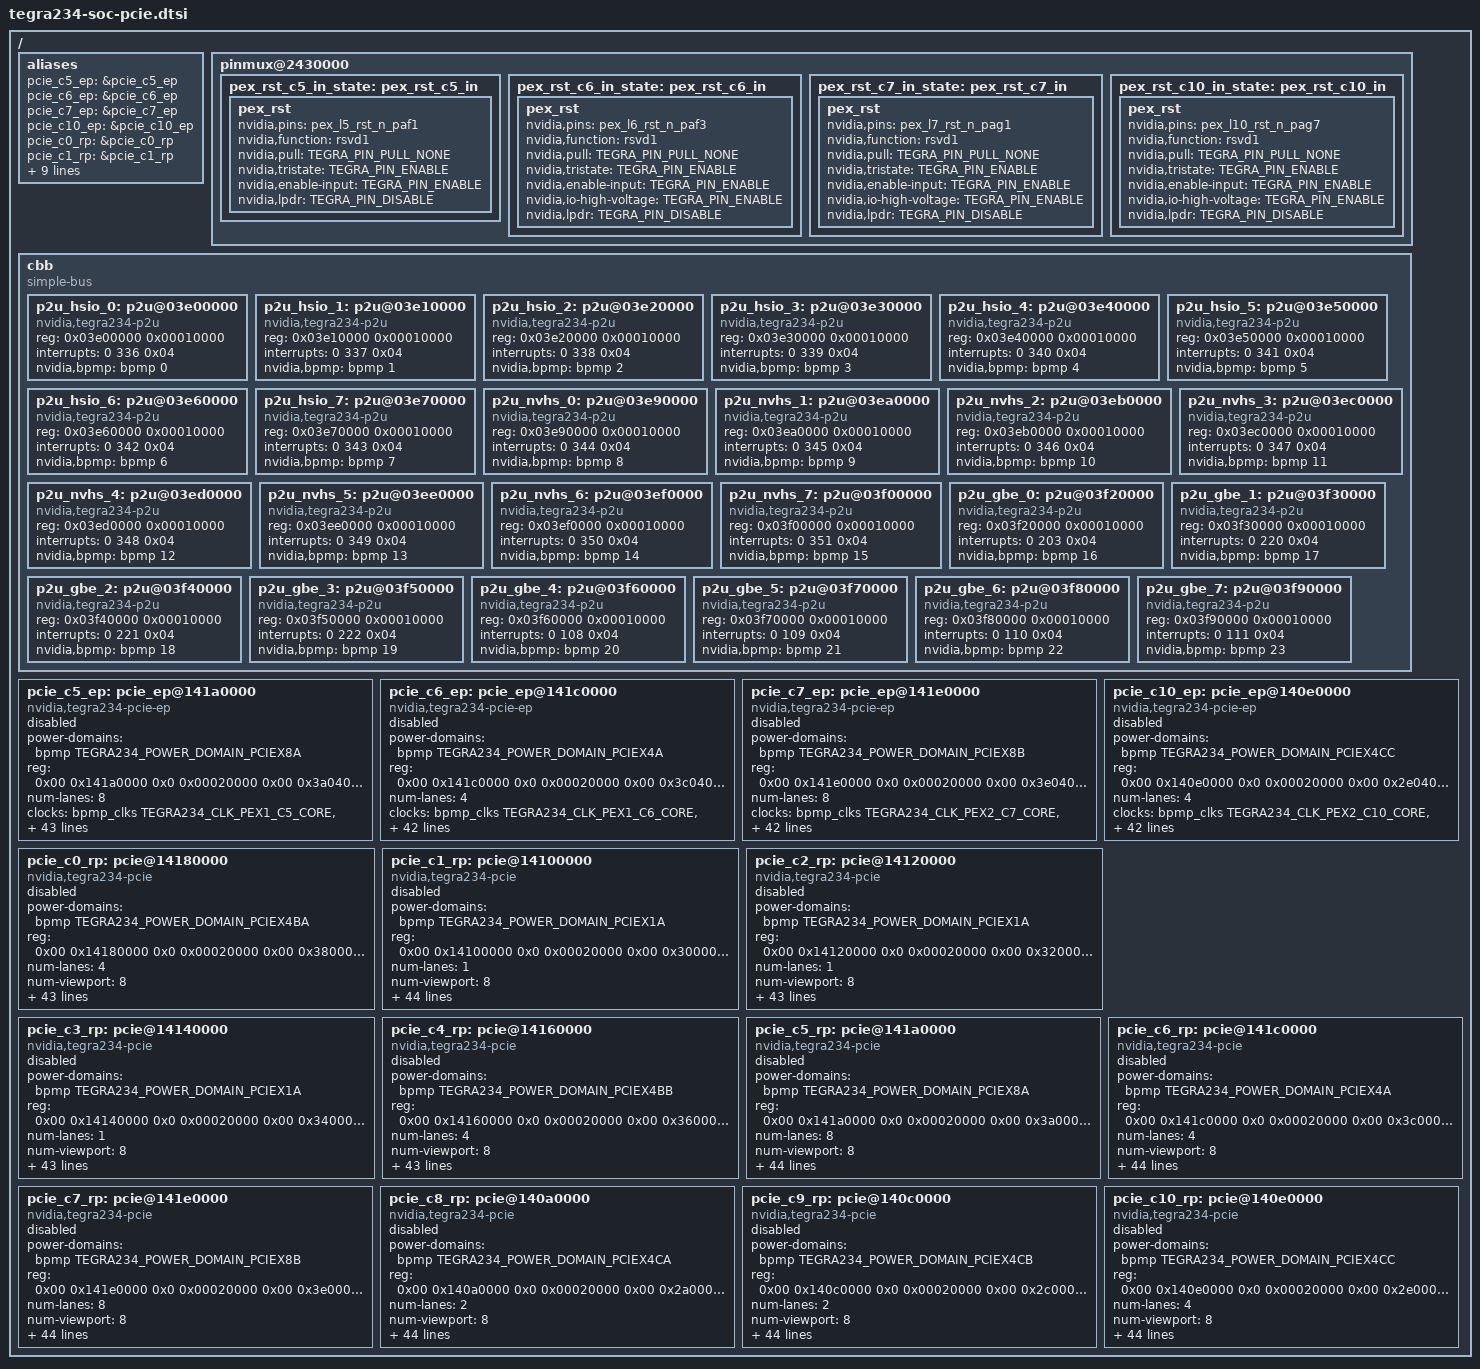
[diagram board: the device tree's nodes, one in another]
/*
 * Copyright (c) 2017-2021, NVIDIA CORPORATION.  All rights reserved.
 *
 * This program is free software; you can redistribute it and/or modify it
 * under the terms and conditions of the GNU General Public License,
 * version 2, as published by the Free Software Foundation.
 *
 * This program is distributed in the hope it will be useful, but WITHOUT
 * ANY WARRANTY; without even the implied warranty of MERCHANTABILITY or
 * FITNESS FOR A PARTICULAR PURPOSE.  See the GNU General Public License for
 * more details.
 *
 * You should have received a copy of the GNU General Public License
 * along with this program.  If not, see <http://www.gnu.org/licenses/>.
 */

#include <dt-bindings/clock/tegra234-clock.h>
#include <dt-bindings/memory/tegra234-mc.h>
#include <dt-bindings/reset/tegra234-reset.h>
#include <dt-bindings/interconnect/tegra_icc_id.h>

/*
 * Power domain to PCIE controller and chiplet mapping
 * +---------+-----------------+---------------+--------------+
 * | Sr. No. | PCIE Controller |    Chiplet    | Power domain |
 * +---------+-----------------+---------------+--------------+
 * |       1 | PCIE_C0         | hsiouphy_pcie | pciex4b (b0) |
 * |       2 | PCIE_C1 *       | hsiouphy_pcie | pciex1a      |
 * |       3 | PCIE_C2 *       | hsiouphy_pcie | pciex1a      |
 * |       4 | PCIE_C3 *       | hsiouphy_pcie | pciex1a      |
 * |       5 | PCIE_C4         | hsiouphy_pcie | pciex4c (b1) |
 * |       6 | PCIE_C5 *       | nvlinkuphy    | pciex8a      |
 * |       7 | PCIE_C6         | nvlinkuphy    | pciex4a      |
 * |       8 | PCIE_C7 *       | mgbeuphy_pcie | pciex8b      |
 * |       9 | PCIE_C8         | mgbeuphy_pcie | pciex4d      |
 * |      10 | PCIE_C9         | mgbeuphy_pcie | pciex4e      |
 * |      11 | PCIE_C10        | mgbeuphy_pcie | pciex4f      |
 * +---------+-----------------+---------------+--------------+
 *
 * *) Power domain in chiplet that needs to be on when other power domains in
 *    the chiplet are on.
 *    I.e. the following "parent-child" relations exists:
 *    pciex1a: pciex4b0, pciex4b1
 *    pciex8a: pciex4a
 *    pciex8b: pciex4d, pciex4e, pciex4f
 *    This "parent-child" relation is taken care in BPMP FW.
 */

/ {

	aliases {
		pcie_c5_ep = &pcie_c5_ep;
		pcie_c6_ep = &pcie_c6_ep;
		pcie_c7_ep = &pcie_c7_ep;
		pcie_c10_ep = &pcie_c10_ep;
		pcie_c0_rp = &pcie_c0_rp;
		pcie_c1_rp = &pcie_c1_rp;
		pcie_c2_rp = &pcie_c2_rp;
		pcie_c3_rp = &pcie_c3_rp;
		pcie_c4_rp = &pcie_c4_rp;
		pcie_c5_rp = &pcie_c5_rp;
		pcie_c6_rp = &pcie_c6_rp;
		pcie_c7_rp = &pcie_c7_rp;
		pcie_c8_rp = &pcie_c8_rp;
		pcie_c9_rp = &pcie_c9_rp;
		pcie_c10_rp = &pcie_c10_rp;
	};

	pinmux@2430000 {

		pex_rst_c5_in_state: pex_rst_c5_in {
			pex_rst {
				nvidia,pins = "pex_l5_rst_n_paf1";
				nvidia,function = "rsvd1";
				nvidia,pull = <TEGRA_PIN_PULL_NONE>;
				nvidia,tristate = <TEGRA_PIN_ENABLE>;
				nvidia,enable-input = <TEGRA_PIN_ENABLE>;
				nvidia,lpdr = <TEGRA_PIN_DISABLE>;
			};
		};

		pex_rst_c6_in_state: pex_rst_c6_in {
			pex_rst {
				nvidia,pins = "pex_l6_rst_n_paf3";
				nvidia,function = "rsvd1";
				nvidia,pull = <TEGRA_PIN_PULL_NONE>;
				nvidia,tristate = <TEGRA_PIN_ENABLE>;
				nvidia,enable-input = <TEGRA_PIN_ENABLE>;
				nvidia,io-high-voltage = <TEGRA_PIN_ENABLE>;
				nvidia,lpdr = <TEGRA_PIN_DISABLE>;
			};
		};

		pex_rst_c7_in_state: pex_rst_c7_in {
			pex_rst {
				nvidia,pins = "pex_l7_rst_n_pag1";
				nvidia,function = "rsvd1";
				nvidia,pull = <TEGRA_PIN_PULL_NONE>;
				nvidia,tristate = <TEGRA_PIN_ENABLE>;
				nvidia,enable-input = <TEGRA_PIN_ENABLE>;
				nvidia,io-high-voltage = <TEGRA_PIN_ENABLE>;
				nvidia,lpdr = <TEGRA_PIN_DISABLE>;
			};
		};

		pex_rst_c10_in_state: pex_rst_c10_in {
			pex_rst {
				nvidia,pins = "pex_l10_rst_n_pag7";
				nvidia,function = "rsvd1";
				nvidia,pull = <TEGRA_PIN_PULL_NONE>;
				nvidia,tristate = <TEGRA_PIN_ENABLE>;
				nvidia,enable-input = <TEGRA_PIN_ENABLE>;
				nvidia,io-high-voltage = <TEGRA_PIN_ENABLE>;
				nvidia,lpdr = <TEGRA_PIN_DISABLE>;
			};
		};

	};

	cbb {
		compatible = "simple-bus";
		#address-cells = <1>;
		#size-cells = <1>;
		ranges = <0x0 0x0 0x0 0x40000000>;

		p2u_hsio_0: p2u@03e00000 {
			compatible = "nvidia,tegra234-p2u";
			reg = <0x03e00000 0x00010000>;
			reg-names = "ctl";

			interrupts = <0 336 0x04>;
			interrupt-names = "intr";

			nvidia,bpmp = <&bpmp 0>;

			#phy-cells = <0>;
		};
		p2u_hsio_1: p2u@03e10000 {
			compatible = "nvidia,tegra234-p2u";
			reg = <0x03e10000 0x00010000>;
			reg-names = "ctl";

			interrupts = <0 337 0x04>;
			interrupt-names = "intr";

			nvidia,bpmp = <&bpmp 1>;

			#phy-cells = <0>;
		};
		p2u_hsio_2: p2u@03e20000 {
			compatible = "nvidia,tegra234-p2u";
			reg = <0x03e20000 0x00010000>;
			reg-names = "ctl";

			interrupts = <0 338 0x04>;
			interrupt-names = "intr";

			nvidia,bpmp = <&bpmp 2>;

			#phy-cells = <0>;
		};
		p2u_hsio_3: p2u@03e30000 {
			compatible = "nvidia,tegra234-p2u";
			reg = <0x03e30000 0x00010000>;
			reg-names = "ctl";

			interrupts = <0 339 0x04>;
			interrupt-names = "intr";

			nvidia,bpmp = <&bpmp 3>;

			#phy-cells = <0>;
		};
		p2u_hsio_4: p2u@03e40000 {
			compatible = "nvidia,tegra234-p2u";
			reg = <0x03e40000 0x00010000>;
			reg-names = "ctl";

			interrupts = <0 340 0x04>;
			interrupt-names = "intr";

			nvidia,bpmp = <&bpmp 4>;

			#phy-cells = <0>;
		};
		p2u_hsio_5: p2u@03e50000 {
			compatible = "nvidia,tegra234-p2u";
			reg = <0x03e50000 0x00010000>;
			reg-names = "ctl";

			interrupts = <0 341 0x04>;
			interrupt-names = "intr";

			nvidia,bpmp = <&bpmp 5>;

			#phy-cells = <0>;
		};
		p2u_hsio_6: p2u@03e60000 {
			compatible = "nvidia,tegra234-p2u";
			reg = <0x03e60000 0x00010000>;
			reg-names = "ctl";

			interrupts = <0 342 0x04>;
			interrupt-names = "intr";

			nvidia,bpmp = <&bpmp 6>;

			#phy-cells = <0>;
		};
		p2u_hsio_7: p2u@03e70000 {
			compatible = "nvidia,tegra234-p2u";
			reg = <0x03e70000 0x00010000>;
			reg-names = "ctl";

			interrupts = <0 343 0x04>;
			interrupt-names = "intr";

			nvidia,bpmp = <&bpmp 7>;

			#phy-cells = <0>;
		};
		p2u_nvhs_0: p2u@03e90000 {
			compatible = "nvidia,tegra234-p2u";
			reg = <0x03e90000 0x00010000>;
			reg-names = "ctl";

			interrupts = <0 344 0x04>;
			interrupt-names = "intr";

			nvidia,bpmp = <&bpmp 8>;

			#phy-cells = <0>;
		};
		p2u_nvhs_1: p2u@03ea0000 {
			compatible = "nvidia,tegra234-p2u";
			reg = <0x03ea0000 0x00010000>;
			reg-names = "ctl";

			interrupts = <0 345 0x04>;
			interrupt-names = "intr";

			nvidia,bpmp = <&bpmp 9>;

			#phy-cells = <0>;
		};
		p2u_nvhs_2: p2u@03eb0000 {
			compatible = "nvidia,tegra234-p2u";
			reg = <0x03eb0000 0x00010000>;
			reg-names = "ctl";

			interrupts = <0 346 0x04>;
			interrupt-names = "intr";

			nvidia,bpmp = <&bpmp 10>;

			#phy-cells = <0>;
		};
		p2u_nvhs_3: p2u@03ec0000 {
			compatible = "nvidia,tegra234-p2u";
			reg = <0x03ec0000 0x00010000>;
			reg-names = "ctl";

			interrupts = <0 347 0x04>;
			interrupt-names = "intr";

			nvidia,bpmp = <&bpmp 11>;

			#phy-cells = <0>;
		};
		p2u_nvhs_4: p2u@03ed0000 {
			compatible = "nvidia,tegra234-p2u";
			reg = <0x03ed0000 0x00010000>;
			reg-names = "ctl";

			interrupts = <0 348 0x04>;
			interrupt-names = "intr";

			nvidia,bpmp = <&bpmp 12>;

			#phy-cells = <0>;
		};
		p2u_nvhs_5: p2u@03ee0000 {
			compatible = "nvidia,tegra234-p2u";
			reg = <0x03ee0000 0x00010000>;
			reg-names = "ctl";

			interrupts = <0 349 0x04>;
			interrupt-names = "intr";

			nvidia,bpmp = <&bpmp 13>;

			#phy-cells = <0>;
		};
		p2u_nvhs_6: p2u@03ef0000 {
			compatible = "nvidia,tegra234-p2u";
			reg = <0x03ef0000 0x00010000>;
			reg-names = "ctl";

			interrupts = <0 350 0x04>;
			interrupt-names = "intr";

			nvidia,bpmp = <&bpmp 14>;

			#phy-cells = <0>;
		};
		p2u_nvhs_7: p2u@03f00000 {
			compatible = "nvidia,tegra234-p2u";
			reg = <0x03f00000 0x00010000>;
			reg-names = "ctl";

			interrupts = <0 351 0x04>;
			interrupt-names = "intr";

			nvidia,bpmp = <&bpmp 15>;

			#phy-cells = <0>;
		};
		p2u_gbe_0: p2u@03f20000 {
			compatible = "nvidia,tegra234-p2u";
			reg = <0x03f20000 0x00010000>;
			reg-names = "ctl";

			interrupts = <0 203 0x04>;
			interrupt-names = "intr";

			nvidia,bpmp = <&bpmp 16>;

			#phy-cells = <0>;
		};
		p2u_gbe_1: p2u@03f30000 {
			compatible = "nvidia,tegra234-p2u";
			reg = <0x03f30000 0x00010000>;
			reg-names = "ctl";

			interrupts = <0 220 0x04>;
			interrupt-names = "intr";

			nvidia,bpmp = <&bpmp 17>;

			#phy-cells = <0>;
		};
		p2u_gbe_2: p2u@03f40000 {
			compatible = "nvidia,tegra234-p2u";
			reg = <0x03f40000 0x00010000>;
			reg-names = "ctl";

			interrupts = <0 221 0x04>;
			interrupt-names = "intr";

			nvidia,bpmp = <&bpmp 18>;

			#phy-cells = <0>;
		};
		p2u_gbe_3: p2u@03f50000 {
			compatible = "nvidia,tegra234-p2u";
			reg = <0x03f50000 0x00010000>;
			reg-names = "ctl";

			interrupts = <0 222 0x04>;
			interrupt-names = "intr";

			nvidia,bpmp = <&bpmp 19>;

			#phy-cells = <0>;
		};
		p2u_gbe_4: p2u@03f60000 {
			compatible = "nvidia,tegra234-p2u";
			reg = <0x03f60000 0x00010000>;
			reg-names = "ctl";

			interrupts = <0 108 0x04>;
			interrupt-names = "intr";

			nvidia,bpmp = <&bpmp 20>;

			#phy-cells = <0>;
		};
		p2u_gbe_5: p2u@03f70000 {
			compatible = "nvidia,tegra234-p2u";
			reg = <0x03f70000 0x00010000>;
			reg-names = "ctl";

			interrupts = <0 109 0x04>;
			interrupt-names = "intr";

			nvidia,bpmp = <&bpmp 21>;

			#phy-cells = <0>;
		};
		p2u_gbe_6: p2u@03f80000 {
			compatible = "nvidia,tegra234-p2u";
			reg = <0x03f80000 0x00010000>;
			reg-names = "ctl";

			interrupts = <0 110 0x04>;
			interrupt-names = "intr";

			nvidia,bpmp = <&bpmp 22>;

			#phy-cells = <0>;
		};
		p2u_gbe_7: p2u@03f90000 {
			compatible = "nvidia,tegra234-p2u";
			reg = <0x03f90000 0x00010000>;
			reg-names = "ctl";

			interrupts = <0 111 0x04>;
			interrupt-names = "intr";

			nvidia,bpmp = <&bpmp 23>;

			#phy-cells = <0>;
		};
	};

	/* C5 X8 */
	pcie_c5_ep: pcie_ep@141a0000 {
		compatible = "nvidia,tegra234-pcie-ep", "snps,dw-pcie";
		power-domains = <&bpmp TEGRA234_POWER_DOMAIN_PCIEX8A>;
		reg = <0x00 0x141a0000 0x0 0x00020000     /* appl registers (128K)      */
			0x00 0x3a040000 0x0 0x00040000    /* iATU_DMA reg space (256K)  */
			0x00 0x3a080000 0x0 0x00040000    /* DBI space (256K)           */
			0x27 0x40000000 0x4 0x00000000>;  /* Address Space (16G)        */
		reg-names = "appl", "atu_dma", "dbi", "addr_space";

		#address-cells = <3>;
		#size-cells = <2>;

		status = "disabled";

		num-lanes = <8>;

		clocks = <&bpmp_clks TEGRA234_CLK_PEX1_C5_CORE>,
			 <&bpmp_clks TEGRA234_CLK_PEX1_C5_CORE_M>;
		clock-names = "core", "core_m";

		resets = <&bpmp_resets TEGRA234_RESET_PEX1_CORE_5_APB>,
			 <&bpmp_resets TEGRA234_RESET_PEX1_CORE_5>;
		reset-names = "apb", "core";

		pinctrl-names = "default";
		pinctrl-0 = <&pex_rst_c5_in_state>;

		interrupts = <0 53 0x04>;	/* controller interrupt */
		interrupt-names = "intr";

		nvidia,dvfs-tbl = < 204000000 204000000 204000000  204000000
				    204000000 204000000 204000000  665600000
				    204000000 204000000 665600000  1600000000
				    204000000 665600000 1600000000 2133000000 >;

		nvidia,host1x = <&host1x>;
		nvidia,enable-ext-refclk;
		nvidia,max-speed = <4>;
		nvidia,bar0-size = <0x100000>;	/* 1 MB */
		nvidia,device-id = /bits/ 16 <0x229B>;
		nvidia,controller-id = <&bpmp 0x5>;
		nvidia,aux-clk-freq = <0x13>;
		nvidia,disable-aspm-states = <0xf>;
		nvidia,aspm-cmrt = <0x3C>;
		nvidia,aspm-pwr-on-t = <0x14>;
		nvidia,aspm-l0s-entrance-latency = <0x3>;
		nvidia,aspm-l1-entrance-latency = <0x5>;

		num-ib-windows = <2>;
		num-ob-windows = <8>;

		iommus = <&smmu_niso0 TEGRA_SID_NISO0_PCIE5>;
		iommu-map = <0x0 &smmu_niso0 TEGRA_SID_NISO0_PCIE5 0x1000>;
		msi-parent = <&gic_v2m TEGRA_SID_NISO0_PCIE5>;
		msi-map = <0x0 &gic_v2m TEGRA_SID_NISO0_PCIE5 0x1000>;
		dma-coherent;
		iommu-map-mask = <0x0>;

		nvidia,cfg-link-cap-l1sub = <0x1c4>;
		nvidia,cap-pl16g-status = <0x174>;
		nvidia,cap-pl16g-cap-off = <0x188>;
		nvidia,event-cntr-ctrl = <0x1d8>;
		nvidia,event-cntr-data = <0x1dc>;
		nvidia,dl-feature-cap = <0x30c>;
		nvidia,ptm-cap-off = <0x318>;

		interconnects = <&tegra_icc TEGRA_ICC_PCIE_5 &tegra_icc TEGRA_ICC_PRIMARY>;
		interconnect-names = "icc_bwmgr";

		nvidia,bpmp = <&bpmp 5>;
		nvidia,aspm-cmrt-us = <60>;
		nvidia,aspm-pwr-on-t-us = <20>;
		nvidia,aspm-l0s-entrance-latency-us = <3>;
	};


	/* C6 X4 */
	pcie_c6_ep: pcie_ep@141c0000{
		compatible = "nvidia,tegra234-pcie-ep", "snps,dw-pcie";
		power-domains = <&bpmp TEGRA234_POWER_DOMAIN_PCIEX4A>;
		reg = <0x00 0x141c0000 0x0 0x00020000     /* appl registers (128K)      */
			0x00 0x3c040000 0x0 0x00040000    /* iATU_DMA reg space (256K)  */
			0x00 0x3c080000 0x0 0x00040000    /* DBI space (256K)           */
			0x2b 0x40000000 0x3 0x00000000>;  /* Address Space (12G)        */
		reg-names = "appl", "atu_dma", "dbi", "addr_space";

		#address-cells = <3>;
		#size-cells = <2>;

		status = "disabled";

		num-lanes = <4>;

		clocks = <&bpmp_clks TEGRA234_CLK_PEX1_C6_CORE>,
			 <&bpmp_clks TEGRA234_CLK_PEX1_C6_CORE_M>;
		clock-names = "core", "core_m";

		resets = <&bpmp_resets TEGRA234_RESET_PEX1_CORE_6_APB>,
			 <&bpmp_resets TEGRA234_RESET_PEX1_CORE_6>;
		reset-names = "apb", "core";

		pinctrl-names = "default";
		pinctrl-0 = <&pex_rst_c6_in_state>;

		interrupts = <0 352 0x04>;	/* controller interrupt */
		interrupt-names = "intr";

		nvidia,dvfs-tbl = < 204000000 204000000 204000000  665600000
				    204000000 204000000 665600000  1600000000
				    204000000 665600000 1600000000 2133000000
				    0         0         0          0 >;

		nvidia,enable-ext-refclk;
		nvidia,max-speed = <4>;
		nvidia,bar0-size = <0x100000>;	/* 1 MB */
		nvidia,device-id = /bits/ 16 <0x229D>;
		nvidia,controller-id = <&bpmp 0x6>;
		nvidia,aux-clk-freq = <0x13>;
		nvidia,disable-aspm-states = <0xf>;
		nvidia,aspm-cmrt = <0x3C>;
		nvidia,aspm-pwr-on-t = <0x14>;
		nvidia,aspm-l0s-entrance-latency = <0x3>;
		nvidia,aspm-l1-entrance-latency = <0x5>;

		num-ib-windows = <2>;
		num-ob-windows = <8>;

		iommus = <&smmu_niso0 TEGRA_SID_NISO0_PCIE6>;
		iommu-map = <0x0 &smmu_niso0 TEGRA_SID_NISO0_PCIE6 0x1000>;
		msi-parent = <&gic_v2m TEGRA_SID_NISO0_PCIE6>;
		msi-map = <0x0 &gic_v2m TEGRA_SID_NISO0_PCIE6 0x1000>;
		dma-coherent;
		iommu-map-mask = <0x0>;

		nvidia,cfg-link-cap-l1sub = <0x1b0>;
		nvidia,cap-pl16g-status = <0x174>;
		nvidia,cap-pl16g-cap-off = <0x188>;
		nvidia,event-cntr-ctrl = <0x1c4>;
		nvidia,event-cntr-data = <0x1c8>;
		nvidia,dl-feature-cap = <0x2f8>;
		nvidia,ptm-cap-off = <0x304>;

		interconnects = <&tegra_icc TEGRA_ICC_PCIE_6 &tegra_icc TEGRA_ICC_PRIMARY>;
		interconnect-names = "icc_bwmgr";

		nvidia,bpmp = <&bpmp 6>;
		nvidia,aspm-cmrt-us = <60>;
		nvidia,aspm-pwr-on-t-us = <20>;
		nvidia,aspm-l0s-entrance-latency-us = <3>;
	};

	/* C7 X8 */
	pcie_c7_ep: pcie_ep@141e0000 {
		compatible = "nvidia,tegra234-pcie-ep", "snps,dw-pcie";
		power-domains = <&bpmp TEGRA234_POWER_DOMAIN_PCIEX8B>;
		reg = <0x00 0x141e0000 0x0 0x00020000     /* appl registers (128K)      */
			0x00 0x3e040000 0x0 0x00040000    /* iATU_DMA reg space (256K)  */
			0x00 0x3e080000 0x0 0x00040000    /* DBI space (256K)           */
			0x2e 0x40000000 0x4 0x00000000>;  /* Address Space (16G)        */
		reg-names = "appl", "atu_dma", "dbi", "addr_space";

		#address-cells = <3>;
		#size-cells = <2>;

		status = "disabled";

		num-lanes = <8>;

		clocks = <&bpmp_clks TEGRA234_CLK_PEX2_C7_CORE>,
			 <&bpmp_clks TEGRA234_CLK_PEX2_C7_CORE_M>;
		clock-names = "core", "core_m";

		resets = <&bpmp_resets TEGRA234_RESET_PEX2_CORE_7_APB>,
			 <&bpmp_resets TEGRA234_RESET_PEX2_CORE_7>;
		reset-names = "apb", "core";

		pinctrl-names = "default";
		pinctrl-0 = <&pex_rst_c7_in_state>;

		interrupts = <0 354 0x04>;	/* controller interrupt */
		interrupt-names = "intr";

		nvidia,dvfs-tbl = < 204000000 204000000 204000000  204000000
				    204000000 204000000 204000000  665600000
				    204000000 204000000 665600000  1600000000
				    204000000 665600000 1600000000 2133000000 >;

		nvidia,enable-ext-refclk;
		nvidia,max-speed = <4>;
		nvidia,bar0-size = <0x100000>;	/* 1 MB */
		nvidia,device-id = /bits/ 16 <0x229B>;
		nvidia,controller-id = <&bpmp 0x7>;
		nvidia,aux-clk-freq = <0x13>;
		nvidia,disable-aspm-states = <0xf>;
		nvidia,aspm-cmrt = <0x3C>;
		nvidia,aspm-pwr-on-t = <0x14>;
		nvidia,aspm-l0s-entrance-latency = <0x3>;
		nvidia,aspm-l1-entrance-latency = <0x5>;

		num-ib-windows = <2>;
		num-ob-windows = <8>;


		iommus = <&smmu_niso1 TEGRA_SID_NISO1_PCIE7>;
		iommu-map = <0x0 &smmu_niso1 TEGRA_SID_NISO1_PCIE7 0x1000>;
		msi-parent = <&gic_v2m TEGRA_SID_NISO1_PCIE7>;
		msi-map = <0x0 &gic_v2m TEGRA_SID_NISO1_PCIE7 0x1000>;
		dma-coherent;
		iommu-map-mask = <0x0>;

		nvidia,cfg-link-cap-l1sub = <0x1c4>;
		nvidia,cap-pl16g-status = <0x174>;
		nvidia,cap-pl16g-cap-off = <0x188>;
		nvidia,event-cntr-ctrl = <0x1d8>;
		nvidia,event-cntr-data = <0x1dc>;
		nvidia,dl-feature-cap = <0x30c>;
		nvidia,ptm-cap-off = <0x318>;

		interconnects = <&tegra_icc TEGRA_ICC_PCIE_7 &tegra_icc TEGRA_ICC_PRIMARY>;
		interconnect-names = "icc_bwmgr";

		nvidia,bpmp = <&bpmp 7>;
		nvidia,aspm-cmrt-us = <60>;
		nvidia,aspm-pwr-on-t-us = <20>;
		nvidia,aspm-l0s-entrance-latency-us = <3>;
	};

	/* C10 X4 */
	pcie_c10_ep: pcie_ep@140e0000 {
		compatible = "nvidia,tegra234-pcie-ep", "snps,dw-pcie";
		power-domains = <&bpmp TEGRA234_POWER_DOMAIN_PCIEX4CC>;
		reg = <0x00 0x140e0000 0x0 0x00020000     /* appl registers (128K)      */
			0x00 0x2e040000 0x0 0x00040000    /* iATU_DMA reg space (256K)  */
			0x00 0x2e080000 0x0 0x00040000    /* DBI space (256K)           */
			0x38 0x40000000 0x3 0x00000000>;  /* Address Space (12G)        */
		reg-names = "appl", "atu_dma", "dbi", "addr_space";

		#address-cells = <3>;
		#size-cells = <2>;

		status = "disabled";

		num-lanes = <4>;

		clocks = <&bpmp_clks TEGRA234_CLK_PEX2_C10_CORE>,
			 <&bpmp_clks TEGRA234_CLK_PEX2_C10_CORE_M>;
		clock-names = "core", "core_m";

		resets = <&bpmp_resets TEGRA234_RESET_PEX2_CORE_10_APB>,
			 <&bpmp_resets TEGRA234_RESET_PEX2_CORE_10>;
		reset-names = "apb", "core";

		pinctrl-names = "default";
		pinctrl-0 = <&pex_rst_c10_in_state>;

		interrupts = <0 360 0x04>;	/* controller interrupt */
		interrupt-names = "intr";

		nvidia,dvfs-tbl = < 204000000 204000000 204000000  665600000
				    204000000 204000000 665600000  1600000000
				    204000000 665600000 1600000000 2133000000
				    0         0         0          0 >;

		nvidia,enable-ext-refclk;
		nvidia,max-speed = <4>;
		nvidia,bar0-size = <0x100000>;	/* 1 MB */
		nvidia,device-id = /bits/ 16 <0x229D>;
		nvidia,controller-id = <&bpmp 0xa>;
		nvidia,aux-clk-freq = <0x13>;
		nvidia,disable-aspm-states = <0xf>;
		nvidia,aspm-cmrt = <0x3C>;
		nvidia,aspm-pwr-on-t = <0x14>;
		nvidia,aspm-l0s-entrance-latency = <0x3>;
		nvidia,aspm-l1-entrance-latency = <0x5>;

		num-ib-windows = <2>;
		num-ob-windows = <8>;


		iommus = <&smmu_niso1 TEGRA_SID_NISO1_PCIE10>;
		iommu-map = <0x0 &smmu_niso1 TEGRA_SID_NISO1_PCIE10 0x1000>;
		msi-parent = <&gic_v2m TEGRA_SID_NISO1_PCIE10>;
		msi-map = <0x0 &gic_v2m TEGRA_SID_NISO1_PCIE10 0x1000>;
		dma-coherent;
		iommu-map-mask = <0x0>;

		nvidia,cfg-link-cap-l1sub = <0x1b0>;
		nvidia,cap-pl16g-status = <0x174>;
		nvidia,cap-pl16g-cap-off = <0x188>;
		nvidia,event-cntr-ctrl = <0x1c4>;
		nvidia,event-cntr-data = <0x1c8>;
		nvidia,dl-feature-cap = <0x2f8>;
		nvidia,ptm-cap-off = <0x304>;

		interconnects = <&tegra_icc TEGRA_ICC_PCIE_10 &tegra_icc TEGRA_ICC_PRIMARY>;
		interconnect-names = "icc_bwmgr";

		nvidia,bpmp = <&bpmp 10>;
		nvidia,aspm-cmrt-us = <60>;
		nvidia,aspm-pwr-on-t-us = <20>;
		nvidia,aspm-l0s-entrance-latency-us = <3>;
	};

	/* C0 X4 */
	pcie_c0_rp: pcie@14180000 {
		compatible = "nvidia,tegra234-pcie", "snps,dw-pcie";
		power-domains = <&bpmp TEGRA234_POWER_DOMAIN_PCIEX4BA>;
		reg = <0x00 0x14180000 0x0 0x00020000   /* appl registers (128K)      */
		       0x00 0x38000000 0x0 0x00040000   /* configuration space (256K) */
		       0x00 0x38040000 0x0 0x00040000   /* iATU_DMA reg space (256K)  */
		       0x00 0x38080000 0x0 0x00040000   /* DBI reg space (256K)       */
		       0x27 0x30000000 0x0 0x10000000>; /* ECAM (256MB)               */
		reg-names = "appl", "config", "atu_dma", "dbi", "ecam";

		status = "disabled";

		#address-cells = <3>;
		#size-cells = <2>;
		device_type = "pci";
		num-lanes = <4>;
		num-viewport = <8>;
		linux,pci-domain = <0>;

		clocks = <&bpmp_clks TEGRA234_CLK_PEX0_C0_CORE>,
			 <&bpmp_clks TEGRA234_CLK_PEX0_C0_CORE_M>;
		clock-names = "core", "core_m";

		resets = <&bpmp_resets TEGRA234_RESET_PEX0_CORE_0_APB>,
			 <&bpmp_resets TEGRA234_RESET_PEX0_CORE_0>;
		reset-names = "apb", "core";

		interrupts = <0 72 0x04>,	/* controller interrupt */
			     <0 73 0x04>;	/* MSI interrupt */
		interrupt-names = "intr", "msi";

		interconnects = <&mc TEGRA234_MEMORY_CLIENT_PCIE0R>,
			        <&mc TEGRA234_MEMORY_CLIENT_PCIE0W>;
		interconnect-names = "dma-mem", "dma-mem";
		iommus = <&smmu_niso0 TEGRA_SID_NISO0_PCIE0>;
		iommu-map = <0x0 &smmu_niso0 TEGRA_SID_NISO0_PCIE0 0x1000>;
		msi-parent = <&gic_v2m TEGRA_SID_NISO0_PCIE0>;
		msi-map = <0x0 &gic_v2m TEGRA_SID_NISO0_PCIE0 0x1000>;

		dma-coherent;
		iommu-map-mask = <0x0>;

		#interrupt-cells = <1>;
		interrupt-map-mask = <0 0 0 0>;
		interrupt-map = <0 0 0 0 &intc 0 72 0x04>;

		nvidia,dvfs-tbl = < 204000000 204000000 204000000  665600000
				    204000000 204000000 665600000  1600000000
				    204000000 665600000 1600000000 2133000000
				    0         0         0          0 >;

		nvidia,max-speed = <4>;
		nvidia,disable-aspm-states = <0xf>;
		nvidia,controller-id = <&bpmp 0x0>;
		nvidia,disable-l1-cpm;
		nvidia,aux-clk-freq = <0x13>;
		nvidia,preset-init = <0x5>;
		nvidia,aspm-cmrt = <0x3C>;
		nvidia,aspm-pwr-on-t = <0x14>;
		nvidia,aspm-l0s-entrance-latency = <0x3>;
		nvidia,bpmp = <&bpmp 0>;
		nvidia,aspm-cmrt-us = <60>;
		nvidia,aspm-pwr-on-t-us = <20>;
		nvidia,aspm-l0s-entrance-latency-us = <3>;

		bus-range = <0x0 0xff>;
		ranges = <0x81000000 0x00 0x38100000 0x00 0x38100000 0x0 0x00100000      /* downstream I/O (1MB) */
			  0x82000000 0x00 0x40000000 0x27 0x28000000 0x0 0x08000000      /* non-prefetchable memory (128MB) */
			  0xc3000000 0x24 0x40000000 0x24 0x40000000 0x2 0xe8000000>;    /* prefetchable memory (11904MB) */

		nvidia,cfg-link-cap-l1sub = <0x1b0>;
		nvidia,cap-pl16g-status = <0x174>;
		nvidia,cap-pl16g-cap-off = <0x188>;
		nvidia,event-cntr-ctrl = <0x1c4>;
		nvidia,event-cntr-data = <0x1c8>;
		nvidia,dl-feature-cap = <0x2f8>;
		nvidia,ptm-cap-off = <0x304>;
	};

	/* C1 X1 */
	pcie_c1_rp: pcie@14100000 {
		compatible = "nvidia,tegra234-pcie", "snps,dw-pcie";
		power-domains = <&bpmp TEGRA234_POWER_DOMAIN_PCIEX1A>;
		reg = <0x00 0x14100000 0x0 0x00020000   /* appl registers (128K)      */
		       0x00 0x30000000 0x0 0x00040000   /* configuration space (256K) */
		       0x00 0x30040000 0x0 0x00040000   /* iATU_DMA reg space (256K)  */
		       0x00 0x30080000 0x0 0x00040000   /* DBI reg space (256K)       */
		       0x20 0xb0000000 0x0 0x10000000>; /* ECAM (256MB)               */
		reg-names = "appl", "config", "atu_dma", "dbi", "ecam";

		status = "disabled";

		#address-cells = <3>;
		#size-cells = <2>;
		device_type = "pci";
		num-lanes = <1>;
		num-viewport = <8>;
		linux,pci-domain = <1>;

		clocks = <&bpmp_clks TEGRA234_CLK_PEX0_C1_CORE>,
			 <&bpmp_clks TEGRA234_CLK_PEX0_C1_CORE_M>;
		clock-names = "core", "core_m";

		resets = <&bpmp_resets TEGRA234_RESET_PEX0_CORE_1_APB>,
			 <&bpmp_resets TEGRA234_RESET_PEX0_CORE_1>;
		reset-names = "apb", "core";

		interrupts = <0 45 0x04>,	/* controller interrupt */
			     <0 46 0x04>;	/* MSI interrupt */
		interrupt-names = "intr", "msi";
		interconnects = <&mc TEGRA234_MEMORY_CLIENT_PCIE1R>,
			        <&mc TEGRA234_MEMORY_CLIENT_PCIE1W>;
		interconnect-names = "dma-mem", "dma-mem";
		iommus = <&smmu_niso1 TEGRA_SID_NISO1_PCIE1>;
		iommu-map = <0x0 &smmu_niso1 TEGRA_SID_NISO1_PCIE1 0x1000>;
		msi-parent = <&gic_v2m TEGRA_SID_NISO1_PCIE1>;
		msi-map = <0x0 &gic_v2m TEGRA_SID_NISO1_PCIE1 0x1000>;
		dma-coherent;
		iommu-map-mask = <0x0>;

		#interrupt-cells = <1>;
		interrupt-map-mask = <0 0 0 0>;
		interrupt-map = <0 0 0 0 &intc 0 45 0x04>;

		nvidia,dvfs-tbl = < 204000000 665600000 665600000  1600000000
				    0         0         0          0
				    0         0         0          0
				    0         0         0          0 >;

		nvidia,max-speed = <4>;
		nvidia,disable-aspm-states = <0xf>;
		nvidia,controller-id = <&bpmp 0x1>;
		nvidia,host1x = <&host1x>;
		nvidia,disable-l1-cpm;
		nvidia,aux-clk-freq = <0x13>;
		nvidia,preset-init = <0x5>;
		nvidia,aspm-cmrt = <0x3C>;
		nvidia,aspm-pwr-on-t = <0x14>;
		nvidia,aspm-l0s-entrance-latency = <0x3>;
		nvidia,bpmp = <&bpmp 1>;
		nvidia,aspm-cmrt-us = <60>;
		nvidia,aspm-pwr-on-t-us = <20>;
		nvidia,aspm-l0s-entrance-latency-us = <3>;

		bus-range = <0x0 0xff>;
		ranges = <0x81000000 0x00 0x30100000 0x00 0x30100000 0x0 0x00100000      /* downstream I/O (1MB) */
			  0x82000000 0x00 0x40000000 0x20 0xa8000000 0x0 0x08000000      /* non-prefetchable memory (128MB) */
			  0xc3000000 0x20 0x80000000 0x20 0x80000000 0x0 0x28000000>;    /* prefetchable memory (640MB) */

		nvidia,cfg-link-cap-l1sub = <0x194>;
		nvidia,cap-pl16g-status = <0x164>;
		nvidia,cap-pl16g-cap-off = <0x178>;
		nvidia,event-cntr-ctrl = <0x1a8>;
		nvidia,event-cntr-data = <0x1ac>;
		nvidia,dl-feature-cap = <0x2dc>;
		nvidia,ptm-cap-off = <0x2e8>;
	};

	/* C2 X1 */
	pcie_c2_rp: pcie@14120000 {
		compatible = "nvidia,tegra234-pcie", "snps,dw-pcie";
		power-domains = <&bpmp TEGRA234_POWER_DOMAIN_PCIEX1A>;
		reg = <0x00 0x14120000 0x0 0x00020000   /* appl registers (128K)      */
		       0x00 0x32000000 0x0 0x00040000   /* configuration space (256K) */
		       0x00 0x32040000 0x0 0x00040000   /* iATU_DMA reg space (256K)  */
		       0x00 0x32080000 0x0 0x00040000   /* DBI reg space (256K)       */
		       0x20 0xf0000000 0x0 0x10000000>; /* ECAM (256MB)               */
		reg-names = "appl", "config", "atu_dma", "dbi", "ecam";

		status = "disabled";

		#address-cells = <3>;
		#size-cells = <2>;
		device_type = "pci";
		num-lanes = <1>;
		num-viewport = <8>;
		linux,pci-domain = <2>;

		clocks = <&bpmp_clks TEGRA234_CLK_PEX0_C2_CORE>,
			 <&bpmp_clks TEGRA234_CLK_PEX0_C2_CORE_M>;
		clock-names = "core", "core_m";

		resets = <&bpmp_resets TEGRA234_RESET_PEX0_CORE_2_APB>,
			 <&bpmp_resets TEGRA234_RESET_PEX0_CORE_2>;
		reset-names = "apb", "core";

		interrupts = <0 47 0x04>,	/* controller interrupt */
			     <0 48 0x04>;	/* MSI interrupt */
		interrupt-names = "intr", "msi";

		interconnects = <&mc TEGRA234_MEMORY_CLIENT_PCIE2AR>,
			        <&mc TEGRA234_MEMORY_CLIENT_PCIE2AW>;
		interconnect-names = "dma-mem", "dma-mem";
		iommus = <&smmu_niso1 TEGRA_SID_NISO1_PCIE2>;
		iommu-map = <0x0 &smmu_niso1 TEGRA_SID_NISO1_PCIE2 0x1000>;
		msi-parent = <&gic_v2m TEGRA_SID_NISO1_PCIE2>;
		msi-map = <0x0 &gic_v2m TEGRA_SID_NISO1_PCIE2 0x1000>;
		dma-coherent;
		iommu-map-mask = <0x0>;

		#interrupt-cells = <1>;
		interrupt-map-mask = <0 0 0 0>;
		interrupt-map = <0 0 0 0 &intc 0 47 0x04>;

		nvidia,dvfs-tbl = < 204000000 665600000 665600000  1600000000
				    0         0         0          0
				    0         0         0          0
				    0         0         0          0 >;

		nvidia,max-speed = <4>;
		nvidia,disable-aspm-states = <0xf>;
		nvidia,controller-id = <&bpmp 0x2>;
		nvidia,disable-l1-cpm;
		nvidia,aux-clk-freq = <0x13>;
		nvidia,preset-init = <0x5>;
		nvidia,aspm-cmrt = <0x3C>;
		nvidia,aspm-pwr-on-t = <0x14>;
		nvidia,aspm-l0s-entrance-latency = <0x3>;
		nvidia,bpmp = <&bpmp 2>;
		nvidia,aspm-cmrt-us = <60>;
		nvidia,aspm-pwr-on-t-us = <20>;
		nvidia,aspm-l0s-entrance-latency-us = <3>;

		bus-range = <0x0 0xff>;
		ranges = <0x81000000 0x00 0x32100000 0x00 0x32100000 0x0 0x00100000      /* downstream I/O (1MB) */
			  0x82000000 0x00 0x40000000 0x20 0xe8000000 0x0 0x08000000      /* non-prefetchable memory (128MB) */
			  0xc3000000 0x20 0xc0000000 0x20 0xc0000000 0x0 0x28000000>;    /* prefetchable memory (640MB) */

		nvidia,cfg-link-cap-l1sub = <0x194>;
		nvidia,cap-pl16g-status = <0x164>;
		nvidia,cap-pl16g-cap-off = <0x178>;
		nvidia,event-cntr-ctrl = <0x1a8>;
		nvidia,event-cntr-data = <0x1ac>;
		nvidia,dl-feature-cap = <0x2dc>;
		nvidia,ptm-cap-off = <0x2e8>;
	};

	/* C3 X1 */
	pcie_c3_rp: pcie@14140000 {
		compatible = "nvidia,tegra234-pcie", "snps,dw-pcie";
		power-domains = <&bpmp TEGRA234_POWER_DOMAIN_PCIEX1A>;
		reg = <0x00 0x14140000 0x0 0x00020000   /* appl registers (128K)      */
		       0x00 0x34000000 0x0 0x00040000   /* configuration space (256K) */
		       0x00 0x34040000 0x0 0x00040000   /* iATU_DMA reg space (256K)  */
		       0x00 0x34080000 0x0 0x00040000   /* DBI reg space (256K)       */
		       0x21 0x30000000 0x0 0x10000000>; /* ECAM (256MB)               */
		reg-names = "appl", "config", "atu_dma", "dbi", "ecam";

		status = "disabled";

		#address-cells = <3>;
		#size-cells = <2>;
		device_type = "pci";
		num-lanes = <1>;
		num-viewport = <8>;
		linux,pci-domain = <3>;

		clocks = <&bpmp_clks TEGRA234_CLK_PEX0_C3_CORE>,
			 <&bpmp_clks TEGRA234_CLK_PEX0_C3_CORE_M>;
		clock-names = "core", "core_m";

		resets = <&bpmp_resets TEGRA234_RESET_PEX0_CORE_3_APB>,
			 <&bpmp_resets TEGRA234_RESET_PEX0_CORE_3>;
		reset-names = "apb", "core";

		interrupts = <0 49 0x04>,	/* controller interrupt */
			     <0 50 0x04>;	/* MSI interrupt */
		interrupt-names = "intr", "msi";

		interconnects = <&mc TEGRA234_MEMORY_CLIENT_PCIE3R>,
			        <&mc TEGRA234_MEMORY_CLIENT_PCIE3W>;
		interconnect-names = "dma-mem", "dma-mem";
		iommus = <&smmu_niso1 TEGRA_SID_NISO1_PCIE3>;
		iommu-map = <0x0 &smmu_niso1 TEGRA_SID_NISO1_PCIE3 0x1000>;
		msi-parent = <&gic_v2m TEGRA_SID_NISO1_PCIE3>;
		msi-map = <0x0 &gic_v2m TEGRA_SID_NISO1_PCIE3 0x1000>;
		dma-coherent;
		iommu-map-mask = <0x0>;

		#interrupt-cells = <1>;
		interrupt-map-mask = <0 0 0 0>;
		interrupt-map = <0 0 0 0 &intc 0 49 0x04>;

		nvidia,dvfs-tbl = < 204000000 665600000 665600000  1600000000
				    0         0         0          0
				    0         0         0          0
				    0         0         0          0 >;

		nvidia,max-speed = <4>;
		nvidia,disable-aspm-states = <0xf>;
		nvidia,controller-id = <&bpmp 0x3>;
		nvidia,disable-l1-cpm;
		nvidia,aux-clk-freq = <0x13>;
		nvidia,preset-init = <0x5>;
		nvidia,aspm-cmrt = <0x3C>;
		nvidia,aspm-pwr-on-t = <0x14>;
		nvidia,aspm-l0s-entrance-latency = <0x3>;
		nvidia,bpmp = <&bpmp 3>;
		nvidia,aspm-cmrt-us = <60>;
		nvidia,aspm-pwr-on-t-us = <20>;
		nvidia,aspm-l0s-entrance-latency-us = <3>;

		bus-range = <0x0 0xff>;
		ranges = <0x81000000 0x00 0x34100000 0x00 0x34100000 0x0 0x00100000      /* downstream I/O (1MB) */
			  0x82000000 0x00 0x40000000 0x21 0x28000000 0x0 0x08000000      /* non-prefetchable memory (128MB) */
			  0xc3000000 0x21 0x00000000 0x21 0x00000000 0x0 0x28000000>;    /* prefetchable memory (640MB) */

		nvidia,cfg-link-cap-l1sub = <0x194>;
		nvidia,cap-pl16g-status = <0x164>;
		nvidia,cap-pl16g-cap-off = <0x178>;
		nvidia,event-cntr-ctrl = <0x1a8>;
		nvidia,event-cntr-data = <0x1ac>;
		nvidia,dl-feature-cap = <0x2dc>;
		nvidia,ptm-cap-off = <0x2e8>;
	};

	/* C4 X4 */
	pcie_c4_rp: pcie@14160000 {
		compatible = "nvidia,tegra234-pcie", "snps,dw-pcie";
		power-domains = <&bpmp TEGRA234_POWER_DOMAIN_PCIEX4BB>;
		reg = <0x00 0x14160000 0x0 0x00020000   /* appl registers (128K)      */
		       0x00 0x36000000 0x0 0x00040000   /* configuration space (256K) */
		       0x00 0x36040000 0x0 0x00040000   /* iATU_DMA reg space (256K)  */
		       0x00 0x36080000 0x0 0x00040000   /* DBI reg space (256K)       */
		       0x24 0x30000000 0x0 0x10000000>; /* ECAM (256MB)               */
		reg-names = "appl", "config", "atu_dma", "dbi", "ecam";

		status = "disabled";

		#address-cells = <3>;
		#size-cells = <2>;
		device_type = "pci";
		num-lanes = <4>;
		num-viewport = <8>;
		linux,pci-domain = <4>;

		clocks = <&bpmp_clks TEGRA234_CLK_PEX0_C4_CORE>,
			 <&bpmp_clks TEGRA234_CLK_PEX0_C4_CORE_M>;
		clock-names = "core", "core_m";

		resets = <&bpmp_resets TEGRA234_RESET_PEX0_CORE_4_APB>,
			 <&bpmp_resets TEGRA234_RESET_PEX0_CORE_4>;
		reset-names = "apb", "core";

		interrupts = <0 51 0x04>,	/* controller interrupt */
			     <0 52 0x04>;	/* MSI interrupt */
		interrupt-names = "intr", "msi";

		interconnects = <&mc TEGRA234_MEMORY_CLIENT_PCIE4R>,
			        <&mc TEGRA234_MEMORY_CLIENT_PCIE4W>;
		interconnect-names = "dma-mem", "dma-mem";
		iommus = <&smmu_niso0 TEGRA_SID_NISO0_PCIE4>;
		iommu-map = <0x0 &smmu_niso0 TEGRA_SID_NISO0_PCIE4 0x1000>;
		msi-parent = <&gic_v2m TEGRA_SID_NISO0_PCIE4>;
		msi-map = <0x0 &gic_v2m TEGRA_SID_NISO0_PCIE4 0x1000>;
		dma-coherent;
		iommu-map-mask = <0x0>;

		#interrupt-cells = <1>;
		interrupt-map-mask = <0 0 0 0>;
		interrupt-map = <0 0 0 0 &intc 0 51 0x04>;

		nvidia,dvfs-tbl = < 204000000 204000000 204000000  665600000
				    204000000 204000000 665600000  1600000000
				    204000000 665600000 1600000000 2133000000
				    0         0         0          0 >;

		nvidia,max-speed = <4>;
		nvidia,disable-aspm-states = <0xf>;
		nvidia,controller-id = <&bpmp 0x4>;
		nvidia,disable-l1-cpm;
		nvidia,aux-clk-freq = <0x13>;
		nvidia,preset-init = <0x5>;
		nvidia,aspm-cmrt = <0x3C>;
		nvidia,aspm-pwr-on-t = <0x14>;
		nvidia,aspm-l0s-entrance-latency = <0x3>;
		nvidia,bpmp = <&bpmp 4>;
		nvidia,aspm-cmrt-us = <60>;
		nvidia,aspm-pwr-on-t-us = <20>;
		nvidia,aspm-l0s-entrance-latency-us = <3>;

		bus-range = <0x0 0xff>;
		ranges = <0x81000000 0x00 0x36100000 0x00 0x36100000 0x0 0x00100000      /* downstream I/O (1MB) */
			  0x82000000 0x00 0x40000000 0x24 0x28000000 0x0 0x08000000      /* non-prefetchable memory (128MB) */
			  0xc3000000 0x21 0x40000000 0x21 0x40000000 0x2 0xe8000000>;    /* prefetchable memory (11904MB) */

		nvidia,cfg-link-cap-l1sub = <0x1b0>;
		nvidia,cap-pl16g-status = <0x174>;
		nvidia,cap-pl16g-cap-off = <0x188>;
		nvidia,event-cntr-ctrl = <0x1c4>;
		nvidia,event-cntr-data = <0x1c8>;
		nvidia,dl-feature-cap = <0x2f8>;
		nvidia,ptm-cap-off = <0x304>;
	};

	/* C5 X8 */
	pcie_c5_rp: pcie@141a0000 {
		compatible = "nvidia,tegra234-pcie", "snps,dw-pcie";
		power-domains = <&bpmp TEGRA234_POWER_DOMAIN_PCIEX8A>;
		reg = <0x00 0x141a0000 0x0 0x00020000   /* appl registers (128K)      */
		       0x00 0x3a000000 0x0 0x00040000   /* configuration space (256K) */
		       0x00 0x3a040000 0x0 0x00040000   /* iATU_DMA reg space (256K)  */
		       0x00 0x3a080000 0x0 0x00040000   /* DBI reg space (256K)       */
		       0x2b 0x30000000 0x0 0x10000000>; /* ECAM (256MB)               */
		reg-names = "appl", "config", "atu_dma", "dbi", "ecam";

		status = "disabled";

		#address-cells = <3>;
		#size-cells = <2>;
		device_type = "pci";
		num-lanes = <8>;
		num-viewport = <8>;
		linux,pci-domain = <5>;

		clocks = <&bpmp_clks TEGRA234_CLK_PEX1_C5_CORE>,
			 <&bpmp_clks TEGRA234_CLK_PEX1_C5_CORE_M>;
		clock-names = "core", "core_m";

		resets = <&bpmp_resets TEGRA234_RESET_PEX1_CORE_5_APB>,
			 <&bpmp_resets TEGRA234_RESET_PEX1_CORE_5>;
		reset-names = "apb", "core";

		interrupts = <0 53 0x04>,	/* controller interrupt */
			     <0 54 0x04>;	/* MSI interrupt */
		interrupt-names = "intr", "msi";

		interconnects = <&mc TEGRA234_MEMORY_CLIENT_PCIE5R>,
			        <&mc TEGRA234_MEMORY_CLIENT_PCIE5W>;
		interconnect-names = "dma-mem", "dma-mem";
		iommus = <&smmu_niso0 TEGRA_SID_NISO0_PCIE5>;
		iommu-map = <0x0 &smmu_niso0 TEGRA_SID_NISO0_PCIE5 0x1000>;
		msi-parent = <&gic_v2m TEGRA_SID_NISO0_PCIE5>;
		msi-map = <0x0 &gic_v2m TEGRA_SID_NISO0_PCIE5 0x1000>;
		dma-coherent;
		iommu-map-mask = <0x0>;

		#interrupt-cells = <1>;
		interrupt-map-mask = <0 0 0 0>;
		interrupt-map = <0 0 0 0 &intc 0 53 0x04>;

		nvidia,dvfs-tbl = < 204000000 204000000 204000000  204000000
				    204000000 204000000 204000000  665600000
				    204000000 204000000 665600000  1600000000
				    204000000 665600000 1600000000 2133000000 >;

		nvidia,max-speed = <4>;
		nvidia,disable-aspm-states = <0xf>;
		nvidia,controller-id = <&bpmp 0x5>;
		nvidia,tsa-config = <0x0200b004>;
		nvidia,disable-l1-cpm;
		nvidia,aux-clk-freq = <0x13>;
		nvidia,preset-init = <0x5>;
		nvidia,aspm-cmrt = <0x3C>;
		nvidia,aspm-pwr-on-t = <0x14>;
		nvidia,aspm-l0s-entrance-latency = <0x3>;
		nvidia,bpmp = <&bpmp 5>;
		nvidia,aspm-cmrt-us = <60>;
		nvidia,aspm-pwr-on-t-us = <20>;
		nvidia,aspm-l0s-entrance-latency-us = <3>;

		bus-range = <0x0 0xff>;
		ranges = <0x81000000 0x00 0x3a100000 0x00 0x3a100000 0x0 0x00100000      /* downstream I/O (1MB) */
			  0x82000000 0x00 0x40000000 0x2b 0x28000000 0x0 0x08000000      /* non-prefetchable memory (128MB) */
			  0xc3000000 0x27 0x40000000 0x27 0x40000000 0x3 0xe8000000>;    /* prefetchable memory (16000MB) */

		nvidia,cfg-link-cap-l1sub = <0x1c4>;
		nvidia,cap-pl16g-status = <0x174>;
		nvidia,cap-pl16g-cap-off = <0x188>;
		nvidia,event-cntr-ctrl = <0x1d8>;
		nvidia,event-cntr-data = <0x1dc>;
		nvidia,dl-feature-cap = <0x30c>;
		nvidia,ptm-cap-off = <0x318>;
	};

	/* C6 X4 */
	pcie_c6_rp: pcie@141c0000{
		compatible = "nvidia,tegra234-pcie", "snps,dw-pcie";
		power-domains = <&bpmp TEGRA234_POWER_DOMAIN_PCIEX4A>;
		reg = <0x00 0x141c0000 0x0 0x00020000   /* appl registers (128K)      */
		       0x00 0x3c000000 0x0 0x00040000   /* configuration space (256K) */
		       0x00 0x3c040000 0x0 0x00040000   /* iATU_DMA reg space (256K)  */
		       0x00 0x3c080000 0x0 0x00040000   /* DBI reg space (256K)       */
		       0x2e 0x30000000 0x0 0x10000000>; /* ECAM (256MB)               */
		reg-names = "appl", "config", "atu_dma", "dbi", "ecam";

		status = "disabled";

		#address-cells = <3>;
		#size-cells = <2>;
		device_type = "pci";
		num-lanes = <4>;
		num-viewport = <8>;
		linux,pci-domain = <6>;

		clocks = <&bpmp_clks TEGRA234_CLK_PEX1_C6_CORE>,
			 <&bpmp_clks TEGRA234_CLK_PEX1_C6_CORE_M>;
		clock-names = "core", "core_m";

		resets = <&bpmp_resets TEGRA234_RESET_PEX1_CORE_6_APB>,
			 <&bpmp_resets TEGRA234_RESET_PEX1_CORE_6>;
		reset-names = "apb", "core";

		interrupts = <0 352 0x04>,	/* controller interrupt */
			     <0 353 0x04>;	/* MSI interrupt */
		interrupt-names = "intr", "msi";

		interconnects = <&mc TEGRA234_MEMORY_CLIENT_PCIE6AR>,
			        <&mc TEGRA234_MEMORY_CLIENT_PCIE6AW>;
		interconnect-names = "dma-mem", "dma-mem";
		iommus = <&smmu_niso0 TEGRA_SID_NISO0_PCIE6>;
		iommu-map = <0x0 &smmu_niso0 TEGRA_SID_NISO0_PCIE6 0x1000>;
		msi-parent = <&gic_v2m TEGRA_SID_NISO0_PCIE6>;
		msi-map = <0x0 &gic_v2m TEGRA_SID_NISO0_PCIE6 0x1000>;
		dma-coherent;
		iommu-map-mask = <0x0>;

		#interrupt-cells = <1>;
		interrupt-map-mask = <0 0 0 0>;
		interrupt-map = <0 0 0 0 &intc 0 352 0x04>;

		nvidia,dvfs-tbl = < 204000000 204000000 204000000  665600000
				    204000000 204000000 665600000  1600000000
				    204000000 665600000 1600000000 2133000000
				    0         0         0          0 >;

		nvidia,max-speed = <4>;
		nvidia,disable-aspm-states = <0xf>;
		nvidia,controller-id = <&bpmp 0x6>;
		nvidia,tsa-config = <0x0200b004>;
		nvidia,disable-l1-cpm;
		nvidia,aux-clk-freq = <0x13>;
		nvidia,preset-init = <0x5>;
		nvidia,aspm-cmrt = <0x3C>;
		nvidia,aspm-pwr-on-t = <0x14>;
		nvidia,aspm-l0s-entrance-latency = <0x3>;
		nvidia,bpmp = <&bpmp 6>;
		nvidia,aspm-cmrt-us = <60>;
		nvidia,aspm-pwr-on-t-us = <20>;
		nvidia,aspm-l0s-entrance-latency-us = <3>;

		bus-range = <0x0 0xff>;
		ranges = <0x81000000 0x00 0x3c100000 0x00 0x3c100000 0x0 0x00100000      /* downstream I/O (1MB) */
			  0x82000000 0x00 0x40000000 0x2e 0x28000000 0x0 0x08000000      /* non-prefetchable memory (128MB) */
			  0xc3000000 0x2b 0x40000000 0x2b 0x40000000 0x2 0xe8000000>;    /* prefetchable memory (11904MB) */

		nvidia,cfg-link-cap-l1sub = <0x1b0>;
		nvidia,cap-pl16g-status = <0x174>;
		nvidia,cap-pl16g-cap-off = <0x188>;
		nvidia,event-cntr-ctrl = <0x1c4>;
		nvidia,event-cntr-data = <0x1c8>;
		nvidia,dl-feature-cap = <0x2f8>;
		nvidia,ptm-cap-off = <0x304>;
	};

	/* C7 X8*/
	pcie_c7_rp: pcie@141e0000 {
		compatible = "nvidia,tegra234-pcie", "snps,dw-pcie";
		power-domains = <&bpmp TEGRA234_POWER_DOMAIN_PCIEX8B>;
		reg = <0x00 0x141e0000 0x0 0x00020000   /* appl registers (128K)      */
		       0x00 0x3e000000 0x0 0x00040000   /* configuration space (256K) */
		       0x00 0x3e040000 0x0 0x00040000   /* iATU_DMA reg space (256K)  */
		       0x00 0x3e080000 0x0 0x00040000   /* DBI reg space (256K)       */
		       0x32 0x30000000 0x0 0x10000000>; /* ECAM (256MB)               */
		reg-names = "appl", "config", "atu_dma", "dbi", "ecam";

		status = "disabled";

		#address-cells = <3>;
		#size-cells = <2>;
		device_type = "pci";
		num-lanes = <8>;
		num-viewport = <8>;
		linux,pci-domain = <7>;

		clocks = <&bpmp_clks TEGRA234_CLK_PEX2_C7_CORE>,
			 <&bpmp_clks TEGRA234_CLK_PEX2_C7_CORE_M>;
		clock-names = "core", "core_m";

		resets = <&bpmp_resets TEGRA234_RESET_PEX2_CORE_7_APB>,
			 <&bpmp_resets TEGRA234_RESET_PEX2_CORE_7>;
		reset-names = "apb", "core";

		interrupts = <0 354 0x04>,	/* controller interrupt */
			     <0 355 0x04>;	/* MSI interrupt */
		interrupt-names = "intr", "msi";

		interconnects = <&mc TEGRA234_MEMORY_CLIENT_PCIE7AR>,
			        <&mc TEGRA234_MEMORY_CLIENT_PCIE7AW>;
		interconnect-names = "dma-mem", "dma-mem";
		iommus = <&smmu_niso1 TEGRA_SID_NISO1_PCIE7>;
		iommu-map = <0x0 &smmu_niso1 TEGRA_SID_NISO1_PCIE7 0x1000>;
		msi-parent = <&gic_v2m TEGRA_SID_NISO1_PCIE7>;
		msi-map = <0x0 &gic_v2m TEGRA_SID_NISO1_PCIE7 0x1000>;
		dma-coherent;
		iommu-map-mask = <0x0>;

		#interrupt-cells = <1>;
		interrupt-map-mask = <0 0 0 0>;
		interrupt-map = <0 0 0 0 &intc 0 354 0x04>;

		nvidia,dvfs-tbl = < 204000000 204000000 204000000  204000000
				    204000000 204000000 204000000  665600000
				    204000000 204000000 665600000  1600000000
				    204000000 665600000 1600000000 2133000000 >;

		nvidia,max-speed = <4>;
		nvidia,disable-aspm-states = <0xf>;
		nvidia,controller-id = <&bpmp 0x7>;
		nvidia,tsa-config = <0x0200b004>;
		nvidia,disable-l1-cpm;
		nvidia,aux-clk-freq = <0x13>;
		nvidia,preset-init = <0x5>;
		nvidia,aspm-cmrt = <0x3C>;
		nvidia,aspm-pwr-on-t = <0x14>;
		nvidia,aspm-l0s-entrance-latency = <0x3>;
		nvidia,bpmp = <&bpmp 7>;
		nvidia,aspm-cmrt-us = <60>;
		nvidia,aspm-pwr-on-t-us = <20>;
		nvidia,aspm-l0s-entrance-latency-us = <3>;

		bus-range = <0x0 0xff>;
		ranges = <0x81000000 0x00 0x3e100000 0x00 0x3e100000 0x0 0x00100000      /* downstream I/O (1MB) */
			  0x82000000 0x00 0x40000000 0x32 0x28000000 0x0 0x08000000      /* non-prefetchable memory (128MB) */
			  0xc3000000 0x2e 0x40000000 0x2e 0x40000000 0x3 0xe8000000>;    /* prefetchable memory (16000MB) */

		nvidia,cfg-link-cap-l1sub = <0x1c4>;
		nvidia,cap-pl16g-status = <0x174>;
		nvidia,cap-pl16g-cap-off = <0x188>;
		nvidia,event-cntr-ctrl = <0x1d8>;
		nvidia,event-cntr-data = <0x1dc>;
		nvidia,dl-feature-cap = <0x30c>;
		nvidia,ptm-cap-off = <0x318>;
	};

	/* C8 X2 */
	pcie_c8_rp: pcie@140a0000 {
		compatible = "nvidia,tegra234-pcie", "snps,dw-pcie";
		power-domains = <&bpmp TEGRA234_POWER_DOMAIN_PCIEX4CA>;
		reg = <0x00 0x140a0000 0x0 0x00020000   /* appl registers (128K)      */
		       0x00 0x2a000000 0x0 0x00040000   /* configuration space (256K) */
		       0x00 0x2a040000 0x0 0x00040000   /* iATU_DMA reg space (256K)  */
		       0x00 0x2a080000 0x0 0x00040000   /* DBI reg space (256K)       */
		       0x35 0x30000000 0x0 0x10000000>; /* ECAM (256MB)               */
		reg-names = "appl", "config", "atu_dma", "dbi", "ecam";

		status = "disabled";

		#address-cells = <3>;
		#size-cells = <2>;
		device_type = "pci";
		num-lanes = <2>;
		num-viewport = <8>;
		linux,pci-domain = <8>;

		clocks = <&bpmp_clks TEGRA234_CLK_PEX2_C8_CORE>,
			 <&bpmp_clks TEGRA234_CLK_PEX2_C8_CORE_M>;
		clock-names = "core", "core_m";

		resets = <&bpmp_resets TEGRA234_RESET_PEX2_CORE_8_APB>,
			 <&bpmp_resets TEGRA234_RESET_PEX2_CORE_8>;
		reset-names = "apb", "core";

		interrupts = <0 356 0x04>,	/* controller interrupt */
			     <0 357 0x04>;	/* MSI interrupt */
		interrupt-names = "intr", "msi";

		interconnects = <&mc TEGRA234_MEMORY_CLIENT_PCIE8AR>,
			        <&mc TEGRA234_MEMORY_CLIENT_PCIE8AW>;
		interconnect-names = "dma-mem", "dma-mem";
		iommus = <&smmu_niso1 TEGRA_SID_NISO1_PCIE8>;
		iommu-map = <0x0 &smmu_niso1 TEGRA_SID_NISO1_PCIE8 0x1000>;
		msi-parent = <&gic_v2m TEGRA_SID_NISO1_PCIE8>;
		msi-map = <0x0 &gic_v2m TEGRA_SID_NISO1_PCIE8 0x1000>;
		dma-coherent;
		iommu-map-mask = <0x0>;

		#interrupt-cells = <1>;
		interrupt-map-mask = <0 0 0 0>;
		interrupt-map = <0 0 0 0 &intc 0 356 0x04>;

		nvidia,dvfs-tbl = < 204000000 204000000 665600000  1600000000
				    204000000 665600000 1600000000 2133000000
				    0         0         0          0
				    0         0         0          0 >;

		nvidia,max-speed = <4>;
		nvidia,disable-aspm-states = <0xf>;
		nvidia,controller-id = <&bpmp 0x8>;
		nvidia,tsa-config = <0x0200b004>;
		nvidia,disable-l1-cpm;
		nvidia,aux-clk-freq = <0x13>;
		nvidia,preset-init = <0x5>;
		nvidia,aspm-cmrt = <0x3C>;
		nvidia,aspm-pwr-on-t = <0x14>;
		nvidia,aspm-l0s-entrance-latency = <0x3>;
		nvidia,bpmp = <&bpmp 8>;
		nvidia,aspm-cmrt-us = <60>;
		nvidia,aspm-pwr-on-t-us = <20>;
		nvidia,aspm-l0s-entrance-latency-us = <3>;

		bus-range = <0x0 0xff>;
		ranges = <0x81000000 0x00 0x2a100000 0x00 0x2a100000 0x0 0x00100000      /* downstream I/O (1MB) */
			  0x82000000 0x00 0x40000000 0x35 0x28000000 0x0 0x08000000      /* non-prefetchable memory (128MB) */
			  0xc3000000 0x32 0x40000000 0x32 0x40000000 0x2 0xe8000000>;    /* prefetchable memory (11904MB) */

		nvidia,cfg-link-cap-l1sub = <0x1b0>;
		nvidia,cap-pl16g-status = <0x174>;
		nvidia,cap-pl16g-cap-off = <0x188>;
		nvidia,event-cntr-ctrl = <0x1c4>;
		nvidia,event-cntr-data = <0x1c8>;
		nvidia,dl-feature-cap = <0x2f8>;
		nvidia,ptm-cap-off = <0x304>;
	};

	/* C9 X2 */
	pcie_c9_rp: pcie@140c0000 {
		compatible = "nvidia,tegra234-pcie", "snps,dw-pcie";
		power-domains = <&bpmp TEGRA234_POWER_DOMAIN_PCIEX4CB>;
		reg = <0x00 0x140c0000 0x0 0x00020000   /* appl registers (128K)      */
		       0x00 0x2c000000 0x0 0x00040000   /* configuration space (256K) */
		       0x00 0x2c040000 0x0 0x00040000   /* iATU_DMA reg space (256K)  */
		       0x00 0x2c080000 0x0 0x00040000   /* DBI reg space (256K)       */
		       0x38 0x30000000 0x0 0x10000000>; /* ECAM (256MB)               */
		reg-names = "appl", "config", "atu_dma", "dbi", "ecam";

		status = "disabled";

		#address-cells = <3>;
		#size-cells = <2>;
		device_type = "pci";
		num-lanes = <2>;
		num-viewport = <8>;
		linux,pci-domain = <9>;

		clocks = <&bpmp_clks TEGRA234_CLK_PEX2_C9_CORE>,
			 <&bpmp_clks TEGRA234_CLK_PEX2_C9_CORE_M>;
		clock-names = "core", "core_m";

		resets = <&bpmp_resets TEGRA234_RESET_PEX2_CORE_9_APB>,
			 <&bpmp_resets TEGRA234_RESET_PEX2_CORE_9>;
		reset-names = "apb", "core";

		interrupts = <0 358 0x04>,	/* controller interrupt */
			     <0 359 0x04>;	/* MSI interrupt */
		interrupt-names = "intr", "msi";

		interconnects = <&mc TEGRA234_MEMORY_CLIENT_PCIE9AR>,
			        <&mc TEGRA234_MEMORY_CLIENT_PCIE9AW>;
		interconnect-names = "dma-mem", "dma-mem";
		iommus = <&smmu_niso0 TEGRA_SID_NISO0_PCIE9>;
		iommu-map = <0x0 &smmu_niso0 TEGRA_SID_NISO0_PCIE9 0x1000>;
		msi-parent = <&gic_v2m TEGRA_SID_NISO0_PCIE9>;
		msi-map = <0x0 &gic_v2m TEGRA_SID_NISO0_PCIE9 0x1000>;
		dma-coherent;
		iommu-map-mask = <0x0>;

		#interrupt-cells = <1>;
		interrupt-map-mask = <0 0 0 0>;
		interrupt-map = <0 0 0 0 &intc 0 358 0x04>;

		nvidia,dvfs-tbl = < 204000000 204000000 665600000  1600000000
				    204000000 665600000 1600000000 2133000000
				    0         0         0          0
				    0         0         0          0 >;

		nvidia,max-speed = <4>;
		nvidia,disable-aspm-states = <0xf>;
		nvidia,controller-id = <&bpmp 0x9>;
		nvidia,tsa-config = <0x0200b004>;
		nvidia,disable-l1-cpm;
		nvidia,aux-clk-freq = <0x13>;
		nvidia,preset-init = <0x5>;
		nvidia,aspm-cmrt = <0x3C>;
		nvidia,aspm-pwr-on-t = <0x14>;
		nvidia,aspm-l0s-entrance-latency = <0x3>;
		nvidia,bpmp = <&bpmp 9>;
		nvidia,aspm-cmrt-us = <60>;
		nvidia,aspm-pwr-on-t-us = <20>;
		nvidia,aspm-l0s-entrance-latency-us = <3>;

		bus-range = <0x0 0xff>;
		ranges = <0x81000000 0x00 0x2c100000 0x00 0x2c100000 0x0 0x00100000      /* downstream I/O (1MB) */
			  0x82000000 0x00 0x40000000 0x38 0x28000000 0x0 0x08000000      /* non-prefetchable memory (128MB) */
			  0xc3000000 0x35 0x40000000 0x35 0x40000000 0x2 0xe8000000>;    /* prefetchable memory (11904MB) */

		nvidia,cfg-link-cap-l1sub = <0x1b0>;
		nvidia,cap-pl16g-status = <0x174>;
		nvidia,cap-pl16g-cap-off = <0x188>;
		nvidia,event-cntr-ctrl = <0x1c4>;
		nvidia,event-cntr-data = <0x1c8>;
		nvidia,dl-feature-cap = <0x2f8>;
		nvidia,ptm-cap-off = <0x304>;
	};

	/* C10 X4 */
	pcie_c10_rp: pcie@140e0000 {
		compatible = "nvidia,tegra234-pcie", "snps,dw-pcie";
		power-domains = <&bpmp TEGRA234_POWER_DOMAIN_PCIEX4CC>;
		reg = <0x00 0x140e0000 0x0 0x00020000   /* appl registers (128K)      */
		       0x00 0x2e000000 0x0 0x00040000   /* configuration space (256K) */
		       0x00 0x2e040000 0x0 0x00040000   /* iATU_DMA reg space (256K)  */
		       0x00 0x2e080000 0x0 0x00040000   /* DBI reg space (256K)       */
		       0x3b 0x30000000 0x0 0x10000000>; /* ECAM (256MB)               */
		reg-names = "appl", "config", "atu_dma", "dbi", "ecam";

		status = "disabled";

		#address-cells = <3>;
		#size-cells = <2>;
		device_type = "pci";
		num-lanes = <4>;
		num-viewport = <8>;
		linux,pci-domain = <10>;

		clocks = <&bpmp_clks TEGRA234_CLK_PEX2_C10_CORE>,
			 <&bpmp_clks TEGRA234_CLK_PEX2_C10_CORE_M>;
		clock-names = "core", "core_m";

		resets = <&bpmp_resets TEGRA234_RESET_PEX2_CORE_10_APB>,
			 <&bpmp_resets TEGRA234_RESET_PEX2_CORE_10>;
		reset-names = "apb", "core";

		interrupts = <0 360 0x04>,	/* controller interrupt */
			     <0 361 0x04>;	/* MSI interrupt */
		interrupt-names = "intr", "msi";

		interconnects = <&mc TEGRA234_MEMORY_CLIENT_PCIE10AR>,
			        <&mc TEGRA234_MEMORY_CLIENT_PCIE10AW>;
		interconnect-names = "dma-mem", "dma-mem";
		iommus = <&smmu_niso1 TEGRA_SID_NISO1_PCIE10>;
		iommu-map = <0x0 &smmu_niso1 TEGRA_SID_NISO1_PCIE10 0x1000>;
		msi-parent = <&gic_v2m TEGRA_SID_NISO1_PCIE10>;
		msi-map = <0x0 &gic_v2m TEGRA_SID_NISO1_PCIE10 0x1000>;
		dma-coherent;
		iommu-map-mask = <0x0>;

		#interrupt-cells = <1>;
		interrupt-map-mask = <0 0 0 0>;
		interrupt-map = <0 0 0 0 &intc 0 360 0x04>;

		nvidia,dvfs-tbl = < 204000000 204000000 204000000  665600000
				    204000000 204000000 665600000  1600000000
				    204000000 665600000 1600000000 2133000000
				    0         0         0          0 >;

		nvidia,max-speed = <4>;
		nvidia,disable-aspm-states = <0xf>;
		nvidia,controller-id = <&bpmp 0xa>;
		nvidia,tsa-config = <0x0200b004>;
		nvidia,disable-l1-cpm;
		nvidia,aux-clk-freq = <0x13>;
		nvidia,preset-init = <0x5>;
		nvidia,aspm-cmrt = <0x3C>;
		nvidia,aspm-pwr-on-t = <0x14>;
		nvidia,aspm-l0s-entrance-latency = <0x3>;
		nvidia,bpmp = <&bpmp 10>;
		nvidia,aspm-cmrt-us = <60>;
		nvidia,aspm-pwr-on-t-us = <20>;
		nvidia,aspm-l0s-entrance-latency-us = <3>;

		bus-range = <0x0 0xff>;
		ranges = <0x81000000 0x00 0x2e100000 0x00 0x2e100000 0x0 0x00100000      /* downstream I/O (1MB) */
			  0x82000000 0x00 0x40000000 0x3b 0x28000000 0x0 0x08000000      /* non-prefetchable memory (128MB) */
			  0xc3000000 0x38 0x40000000 0x38 0x40000000 0x2 0xe8000000>;    /* prefetchable memory (11904MB) */

		nvidia,cfg-link-cap-l1sub = <0x1b0>;
		nvidia,cap-pl16g-status = <0x174>;
		nvidia,cap-pl16g-cap-off = <0x188>;
		nvidia,event-cntr-ctrl = <0x1c4>;
		nvidia,event-cntr-data = <0x1c8>;
		nvidia,dl-feature-cap = <0x2f8>;
		nvidia,ptm-cap-off = <0x304>;
	};
};
